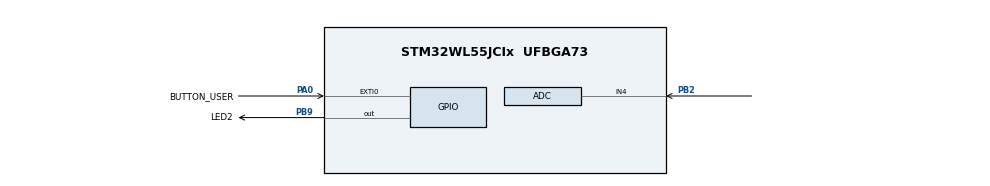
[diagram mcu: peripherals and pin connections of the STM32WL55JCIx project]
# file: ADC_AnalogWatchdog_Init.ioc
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ADC.AWD1HighThreshold=ADC_AWD_THRESHOLD_HIGH
ADC.AWD1ITMode=ENABLE
ADC.AWD1LowThreshold=ADC_AWD_THRESHOLD_LOW
ADC.Channel-0\#ChannelRegularConversion=ADC_CHANNEL_4
ADC.ClockPrescaler=ADC_CLOCK_SYNC_PCLK_DIV4
ADC.ContinuousConvMode=ENABLE
ADC.DMAContinuousRequests=DISABLE
ADC.DataAlign=ADC_DATAALIGN_RIGHT
ADC.DiscontinuousConvMode=DISABLE
ADC.EOCSelection=ADC_EOC_SINGLE_CONV
ADC.EnableAnalogWatchDog1=true
ADC.EnableAnalogWatchDog2=false
ADC.EnableAnalogWatchDog3=false
ADC.EnableRegularConversion=ENABLE
ADC.ExternalTrigConv=ADC_SOFTWARE_START
ADC.ExternalTrigConvEdge=ADC_EXTERNALTRIGCONVEDGE_NONE
ADC.LowPowerAutoPowerOff=DISABLE
ADC.LowPowerAutoWait=DISABLE
ADC.NbrOfConversion=1
ADC.NbrOfConversionFlag=1
ADC.Overrun=ADC_OVR_DATA_OVERWRITTEN
ADC.OversamplingMode=DISABLE
ADC.Rank-0\#ChannelRegularConversion=1
ADC.Resolution=ADC_RESOLUTION_12B
ADC.SamplingTime-0\#ChannelRegularConversion=ADC_SAMPLINGTIME_COMMON_1
ADC.SamplingTimeCommon1=ADC_SAMPLETIME_160CYCLES_5
ADC.SamplingTimeCommon2=ADC_SAMPLETIME_160CYCLES_5
ADC.ScanConvMode=ADC_SCAN_DISABLE
ADC.SelectedChannel=ADC_CHANNEL_4|ADC_CHANNEL_VREFINT
ADC.Sequencer=FULLY_CONFIGURABLE
ADC.TriggerFrequencyMode=ADC_TRIGGER_FREQ_HIGH
ADC.WatchdogMode=ADC_ANALOGWATCHDOG_ALL_REG
Mcu.Family=STM32WL
Mcu.Name=STM32WL55JCIx
Mcu.Package=UFBGA73
NVIC.EXTI0_IRQn=true\:0\:0\:false\:false\:true\:true\:true
NVIC.PriorityGroup=NVIC_PRIORITYGROUP_4
PA0.GPIO_Label=BUTTON_USER
PA0.GPIO_ModeDefaultEXTI=GPIO_MODE_IT_FALLING
PA0.GPIO_PuPd=GPIO_PULLUP
PA0.Signal=GPXTI0
PB2.Mode=IN4
PB2.Signal=ADC_IN4
PB9.GPIO_Label=LED2
PB9.Signal=GPIO_Output
ProjectManager.HeapSize=0x200
ProjectManager.StackSize=0x400
ProjectManager.TargetToolchain=EWARM V8
RCC.AHBFreq_Value=48000000
RCC.APB1Freq_Value=48000000
RCC.APB1TimFreq_Value=48000000
RCC.APB2Freq_Value=48000000
RCC.APB2TimFreq_Value=48000000
RCC.APB3Freq_Value=48000000
RCC.CortexFreq_Value=48000000
RCC.HCLKFreq_Value=48000000
RCC.HSE_VALUE=8000000
RCC.HSI_VALUE=16000000
RCC.LSE_VALUE=32768
RCC.MSIClockRange=RCC_MSIRANGE_11
RCC.SYSCLKFreq_VALUE=48000000
RCC.VCOOutputFreq_Value=384000000
VP_ADC_Vref_Input.Mode=IN-Vrefint
board=custom

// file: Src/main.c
/* USER CODE BEGIN Header */
/**
  ******************************************************************************
  * @file    Examples_LL/ADC/ADC_AnalogWatchdog_Init/Src/main.c
  * @author  MCD Application Team
  * @brief   This example describes how to use a ADC peripheral
  *          with ADC analog watchdog to monitor a channel and detect
  *          when the corresponding conversion data is out of window thresholds.
  *          This example is based on the STM32WLxx ADC LL API;
  *          Peripheral initialization done using LL unitary services functions.
  ******************************************************************************
  * @attention
  *
  * <h2><center>&copy; Copyright (c) 2020 STMicroelectronics.
  * All rights reserved.</center></h2>
  *
  * This software component is licensed by ST under BSD 3-Clause license,
  * the "License"; You may not use this file except in compliance with the
  * License. You may obtain a copy of the License at:
  *                        opensource.org/licenses/BSD-3-Clause
  *
  ******************************************************************************
  */
/* USER CODE END Header */
#include "main.h"

/* USER CODE BEGIN PD */

/* Definitions of ADC hardware constraints delays */
/* Note: Only ADC IP HW delays are defined in ADC LL driver driver,           */
/*       not timeout values:                                                  */
/*       Timeout values for ADC operations are dependent to device clock      */
/*       configuration (system clock versus ADC clock),                       */
/*       and therefore must be defined in user application.                   */
/*       Refer to @ref ADC_LL_EC_HW_DELAYS for description of ADC timeout     */
/*       values definition.                                                   */

  /* Timeout values for ADC operations. */
  /* (calibration, enable settling time, disable settling time, ...)          */
  /* Values defined to be higher than worst cases: low clock frequency,       */
  /* maximum prescalers.                                                      */
  /* Unit: ms                                                                 */
  #define ADC_CALIBRATION_TIMEOUT_MS       (   1U)
  #define ADC_ENABLE_TIMEOUT_MS            (   1U)
  #define ADC_DISABLE_TIMEOUT_MS           (   1U)
  #define ADC_STOP_CONVERSION_TIMEOUT_MS   (   1U)
  #define ADC_CONVERSION_TIMEOUT_MS        (4000U)

  /* Delay between ADC end of calibration and ADC enable.                     */
  /* Delay estimation in CPU cycles: Case of ADC enable done                  */
  /* immediately after ADC calibration, ADC clock setting slow                */
  /* (LL_ADC_CLOCK_ASYNC_DIV32). Use a higher delay if ratio                  */
  /* (CPU clock / ADC clock) is above 32.                                     */
  #define ADC_DELAY_CALIB_ENABLE_CPU_CYCLES  (LL_ADC_DELAY_CALIB_ENABLE_ADC_CYCLES * 32)

/* Definitions of environment analog values */
  /* Value of analog reference voltage (Vref+), connected to analog voltage   */
  /* supply Vdda (unit: mV).                                                  */
  #define VDDA_APPLI                       (3300UL)

/* Definitions of data related to this example */
  /* Definition of ADCx analog watchdog window thresholds */
  /* Value of ADC analog watchdog threshold high */
  #define ADC_AWD_THRESHOLD_HIGH           (__LL_ADC_DIGITAL_SCALE(LL_ADC_RESOLUTION_12B) / 2)
  /* Value of ADC analog watchdog threshold low  */
  #define ADC_AWD_THRESHOLD_LOW            (   0UL)

/* USER CODE END PD */

/* USER CODE BEGIN PV */

/* Variable to report status of ADC analog watchdog 1:                        */
/*  0: ADC conversion data into AWD window                                    */
/*  1: ADC conversion data out of AWD window                                  */
__IO   uint8_t ubAnalogWatchdog1Status = 0U; /* Variable set into analog watchdog 1 interruption callback */

/* USER CODE END PV */

void SystemClock_Config(void);
static void MX_GPIO_Init(void);
static void MX_ADC_Init(void);
/* USER CODE BEGIN PFP */

void     Activate_ADC(void);
void     LED_On(void);
void     LED_Off(void);
void     LED_Blinking(uint32_t Period);

/* USER CODE END PFP */

int main(void)
{

  /* MCU Configuration--------------------------------------------------------*/

  /* Reset of all peripherals, Initializes the Flash interface and the Systick. */

  NVIC_SetPriorityGrouping(NVIC_PRIORITYGROUP_4);

  /* System interrupt init*/

  /* Configure the system clock */
  SystemClock_Config();

  /* Initialize all configured peripherals */
  MX_GPIO_Init();
  MX_ADC_Init();
  /* USER CODE BEGIN 2 */

  /* Activate ADC */
  /* Perform ADC activation procedure to make it ready to convert. */
  Activate_ADC();

  /* Start ADC group regular conversion */
  /* Note: Hardware constraint (refer to description of the functions         */
  /*       below):                                                            */
  /*       On this STM32 series, setting of this feature is conditioned to     */
  /*       ADC state:                                                         */
  /*       ADC must be enabled without conversion on going on group regular,  */
  /*       without ADC disable command on going.                              */
  /* Note: In this example, all these checks are not necessary but are        */
  /*       implemented anyway to show the best practice usages                */
  /*       corresponding to reference manual procedure.                       */
  /*       Software can be optimized by removing some of these checks, if     */
  /*       they are not relevant considering previous settings and actions    */
  /*       in user application.                                               */
  if ((LL_ADC_IsEnabled(ADC) == 1)               &&
      (LL_ADC_IsDisableOngoing(ADC) == 0)        &&
      (LL_ADC_REG_IsConversionOngoing(ADC) == 0)   )
  {
    LL_ADC_REG_StartConversion(ADC);
  }
  else
  {
    /* Error: ADC conversion start could not be performed */
    LED_Blinking(LED_BLINK_ERROR);
  }

  /* USER CODE END 2 */

  /* Infinite loop */
  while (1)
  {

    /* USER CODE BEGIN 3 */
    /* Note: LED state depending on ADC analog watchdog 1 status              */
    /*       and status variable "ubAnalogWatchdog1Status"                    */
    /*       are set into ADC analog watchdog 1 IRQ handler,                  */
    /*       refer to function "AdcAnalogWatchdog1_Callback()".               */
    /*       After analog watchdog interruption, press on push button         */
    /*       to rearm ADC analog watchdog to be ready for another trig,       */
    /*       refer to function "UserButton_Callback()".                       */
  }
  /* USER CODE END 3 */
}

void SystemClock_Config(void)
{
  LL_FLASH_SetLatency(LL_FLASH_LATENCY_2);
  while(LL_FLASH_GetLatency() != LL_FLASH_LATENCY_2)
  {
  }

  LL_PWR_SetRegulVoltageScaling(LL_PWR_REGU_VOLTAGE_SCALE1);
  LL_RCC_MSI_Enable();

   /* Wait till MSI is ready */
  while(LL_RCC_MSI_IsReady() != 1)
  {
  }

  LL_RCC_MSI_EnableRangeSelection();
  LL_RCC_MSI_SetRange(LL_RCC_MSIRANGE_11);
  LL_RCC_MSI_SetCalibTrimming(0);
  LL_RCC_SetSysClkSource(LL_RCC_SYS_CLKSOURCE_MSI);

   /* Wait till System clock is ready */
  while(LL_RCC_GetSysClkSource() != LL_RCC_SYS_CLKSOURCE_STATUS_MSI)
  {
  }

  LL_RCC_SetAHBPrescaler(LL_RCC_SYSCLK_DIV_1);
  LL_RCC_SetAHB3Prescaler(LL_RCC_SYSCLK_DIV_1);
  LL_RCC_SetAPB1Prescaler(LL_RCC_APB1_DIV_1);
  LL_RCC_SetAPB2Prescaler(LL_RCC_APB2_DIV_1);

  LL_Init1msTick(48000000);

  /* Update CMSIS variable (which can be updated also through SystemCoreClockUpdate function) */
  LL_SetSystemCoreClock(48000000);
}

static void MX_ADC_Init(void)
{

  LL_ADC_InitTypeDef ADC_InitStruct = {0};
  LL_ADC_REG_InitTypeDef ADC_REG_InitStruct = {0};

  LL_GPIO_InitTypeDef GPIO_InitStruct = {0};

  /* Peripheral clock enable */
  LL_APB2_GRP1_EnableClock(LL_APB2_GRP1_PERIPH_ADC);

  LL_AHB2_GRP1_EnableClock(LL_AHB2_GRP1_PERIPH_GPIOB);
  /**ADC GPIO Configuration
  PB2   ------> ADC_IN4
  */
  GPIO_InitStruct.Pin = LL_GPIO_PIN_2;
  GPIO_InitStruct.Mode = LL_GPIO_MODE_ANALOG;
  GPIO_InitStruct.Pull = LL_GPIO_PULL_NO;
  LL_GPIO_Init(GPIOB, &GPIO_InitStruct);

  /* USER CODE BEGIN ADC_Init 1 */

  /* Enable GPIO Clock */
  LL_AHB2_GRP1_EnableClock(LL_AHB2_GRP1_PERIPH_GPIOB);

  /* Configure GPIO in analog mode to be used as ADC input */
  LL_GPIO_SetPinMode(GPIOB, LL_GPIO_PIN_2, LL_GPIO_MODE_ANALOG);

  /*## Configuration of NVIC #################################################*/
  /* Configure NVIC to enable ADC interruptions */
  NVIC_SetPriority(ADC_IRQn, 0);
  NVIC_EnableIRQ(ADC_IRQn);

  /* USER CODE END ADC_Init 1 */
  /** Configure the global features of the ADC (Clock, Resolution, Data Alignment and number of conversion)
  */

   #define ADC_CHANNEL_CONF_RDY_TIMEOUT_MS ( 1U)
   #if (USE_TIMEOUT == 1)
   uint32_t Timeout ; /* Variable used for Timeout management */
   #endif /* USE_TIMEOUT */

  ADC_InitStruct.Clock = LL_ADC_CLOCK_SYNC_PCLK_DIV4;
  ADC_InitStruct.Resolution = LL_ADC_RESOLUTION_12B;
  ADC_InitStruct.DataAlignment = LL_ADC_DATA_ALIGN_RIGHT;
  ADC_InitStruct.LowPowerMode = LL_ADC_LP_MODE_NONE;
  LL_ADC_Init(ADC, &ADC_InitStruct);
  LL_ADC_REG_SetSequencerConfigurable(ADC, LL_ADC_REG_SEQ_CONFIGURABLE);

   /* Poll for ADC channel configuration ready */
   #if (USE_TIMEOUT == 1)
   Timeout = ADC_CHANNEL_CONF_RDY_TIMEOUT_MS;
   #endif /* USE_TIMEOUT */
   while (LL_ADC_IsActiveFlag_CCRDY(ADC) == 0)
     {
   #if (USE_TIMEOUT == 1)
   /* Check Systick counter flag to decrement the time-out value */
   if (LL_SYSTICK_IsActiveCounterFlag())
     {
   if(Timeout-- == 0)
         {
   Error_Handler();
         }
     }
   #endif /* USE_TIMEOUT */
     }
   /* Clear flag ADC channel configuration ready */
   LL_ADC_ClearFlag_CCRDY(ADC);
  ADC_REG_InitStruct.TriggerSource = LL_ADC_REG_TRIG_SOFTWARE;
  ADC_REG_InitStruct.SequencerLength = LL_ADC_REG_SEQ_SCAN_DISABLE;
  ADC_REG_InitStruct.SequencerDiscont = LL_ADC_REG_SEQ_DISCONT_DISABLE;
  ADC_REG_InitStruct.ContinuousMode = LL_ADC_REG_CONV_CONTINUOUS;
  ADC_REG_InitStruct.DMATransfer = LL_ADC_REG_DMA_TRANSFER_NONE;
  ADC_REG_InitStruct.Overrun = LL_ADC_REG_OVR_DATA_OVERWRITTEN;
  LL_ADC_REG_Init(ADC, &ADC_REG_InitStruct);

   /* Enable ADC internal voltage regulator */
   LL_ADC_EnableInternalRegulator(ADC);
   /* Delay for ADC internal voltage regulator stabilization. */
   /* Compute number of CPU cycles to wait for, from delay in us. */
   /* Note: Variable divided by 2 to compensate partially */
   /* CPU processing cycles (depends on compilation optimization). */
   /* Note: If system core clock frequency is below 200kHz, wait time */
   /* is only a few CPU processing cycles. */
   uint32_t wait_loop_index;
   wait_loop_index = ((LL_ADC_DELAY_INTERNAL_REGUL_STAB_US * (SystemCoreClock / (100000 * 2))) / 10);
   while(wait_loop_index != 0)
     {
   wait_loop_index--;
     }
  LL_ADC_SetOverSamplingScope(ADC, LL_ADC_OVS_DISABLE);
  LL_ADC_SetSamplingTimeCommonChannels(ADC, LL_ADC_SAMPLINGTIME_COMMON_1, LL_ADC_SAMPLINGTIME_160CYCLES_5);
  LL_ADC_SetSamplingTimeCommonChannels(ADC, LL_ADC_SAMPLINGTIME_COMMON_2, LL_ADC_SAMPLINGTIME_160CYCLES_5);
  LL_ADC_DisableIT_EOC(ADC);
  LL_ADC_DisableIT_EOS(ADC);
  LL_ADC_SetTriggerFrequencyMode(ADC, LL_ADC_TRIGGER_FREQ_HIGH);
  /** Configure Analog WatchDog 1
  */
  LL_ADC_SetAnalogWDMonitChannels(ADC, LL_ADC_AWD1, LL_ADC_AWD_ALL_CHANNELS_REG);
  LL_ADC_ConfigAnalogWDThresholds(ADC, LL_ADC_AWD1, ADC_AWD_THRESHOLD_HIGH, ADC_AWD_THRESHOLD_LOW);
  LL_ADC_EnableIT_AWD1(ADC);
  /** Configure Regular Channel
  */
  LL_ADC_REG_SetSequencerRanks(ADC, LL_ADC_REG_RANK_1, LL_ADC_CHANNEL_4);

   /* Poll for ADC channel configuration ready */
   #if (USE_TIMEOUT == 1)
   Timeout = ADC_CHANNEL_CONF_RDY_TIMEOUT_MS;
   #endif /* USE_TIMEOUT */
   while (LL_ADC_IsActiveFlag_CCRDY(ADC) == 0)
     {
   #if (USE_TIMEOUT == 1)
   /* Check Systick counter flag to decrement the time-out value */
   if (LL_SYSTICK_IsActiveCounterFlag())
     {
   if(Timeout-- == 0)
         {
   Error_Handler();
         }
     }
   #endif /* USE_TIMEOUT */
     }
   /* Clear flag ADC channel configuration ready */
   LL_ADC_ClearFlag_CCRDY(ADC);
  LL_ADC_SetChannelSamplingTime(ADC, LL_ADC_CHANNEL_4, LL_ADC_SAMPLINGTIME_COMMON_1);

}

static void MX_GPIO_Init(void)
{
  LL_EXTI_InitTypeDef EXTI_InitStruct = {0};
  LL_GPIO_InitTypeDef GPIO_InitStruct = {0};

  /* GPIO Ports Clock Enable */
  LL_AHB2_GRP1_EnableClock(LL_AHB2_GRP1_PERIPH_GPIOB);
  LL_AHB2_GRP1_EnableClock(LL_AHB2_GRP1_PERIPH_GPIOA);

  /**/
  LL_GPIO_ResetOutputPin(LED2_GPIO_Port, LED2_Pin);

  /**/
  GPIO_InitStruct.Pin = LED2_Pin;
  GPIO_InitStruct.Mode = LL_GPIO_MODE_OUTPUT;
  GPIO_InitStruct.Speed = LL_GPIO_SPEED_FREQ_LOW;
  GPIO_InitStruct.OutputType = LL_GPIO_OUTPUT_PUSHPULL;
  GPIO_InitStruct.Pull = LL_GPIO_PULL_NO;
  LL_GPIO_Init(LED2_GPIO_Port, &GPIO_InitStruct);

  /**/
  LL_SYSCFG_SetEXTISource(LL_SYSCFG_EXTI_PORTA, LL_SYSCFG_EXTI_LINE0);

  /**/
  EXTI_InitStruct.Line_0_31 = LL_EXTI_LINE_0;
  EXTI_InitStruct.Line_32_63 = LL_EXTI_LINE_NONE;
  EXTI_InitStruct.LineCommand = ENABLE;
  EXTI_InitStruct.Mode = LL_EXTI_MODE_IT;
  EXTI_InitStruct.Trigger = LL_EXTI_TRIGGER_FALLING;
  LL_EXTI_Init(&EXTI_InitStruct);

  /**/
  LL_GPIO_SetPinPull(BUTTON_USER_GPIO_Port, BUTTON_USER_Pin, LL_GPIO_PULL_UP);

  /**/
  LL_GPIO_SetPinMode(BUTTON_USER_GPIO_Port, BUTTON_USER_Pin, LL_GPIO_MODE_INPUT);

  /* EXTI interrupt init*/
  NVIC_SetPriority(EXTI0_IRQn, NVIC_EncodePriority(NVIC_GetPriorityGrouping(),0, 0));
  NVIC_EnableIRQ(EXTI0_IRQn);

}

/* USER CODE BEGIN 4 */

/**
  * @brief  Perform ADC activation procedure to make it ready to convert
  *         (ADC instance: ADC).
  * @note   Operations:
  *         - ADC instance
  *           - Run ADC self calibration
  *           - Enable ADC
  *         - ADC group regular
  *           none: ADC conversion start-stop to be performed
  *                 after this function
  *         - ADC group injected
  *           Feature not available                                  (feature not available on this STM32 series)
  * @param  None
  * @retval None
  */
void Activate_ADC(void)
{
  __IO uint32_t wait_loop_index = 0U;
  __IO uint32_t backup_setting_adc_dma_transfer = 0U;
  #if (USE_TIMEOUT == 1)
  uint32_t Timeout = 0U; /* Variable used for timeout management */
  #endif /* USE_TIMEOUT */

  /*## Operation on ADC hierarchical scope: ADC instance #####################*/

  /* Note: Hardware constraint (refer to description of the functions         */
  /*       below):                                                            */
  /*       On this STM32 series, setting of these features is conditioned to   */
  /*       ADC state:                                                         */
  /*       ADC must be disabled.                                              */
  /* Note: In this example, all these checks are not necessary but are        */
  /*       implemented anyway to show the best practice usages                */
  /*       corresponding to reference manual procedure.                       */
  /*       Software can be optimized by removing some of these checks, if     */
  /*       they are not relevant considering previous settings and actions    */
  /*       in user application.                                               */
  if (LL_ADC_IsEnabled(ADC) == 0)
  {
    /* Enable ADC internal voltage regulator */
    LL_ADC_EnableInternalRegulator(ADC);

    /* Delay for ADC internal voltage regulator stabilization.                */
    /* Compute number of CPU cycles to wait for, from delay in us.            */
    /* Note: Variable divided by 2 to compensate partially                    */
    /*       CPU processing cycles (depends on compilation optimization).     */
    /* Note: If system core clock frequency is below 200kHz, wait time        */
    /*       is only a few CPU processing cycles.                             */
    wait_loop_index = ((LL_ADC_DELAY_INTERNAL_REGUL_STAB_US * (SystemCoreClock / (100000 * 2))) / 10);
    while(wait_loop_index != 0)
    {
      wait_loop_index--;
    }

    /* Disable ADC DMA transfer request during calibration */
    /* Note: Specificity of this STM32 series: Calibration factor is           */
    /*       available in data register and also transferred by DMA.           */
    /*       To not insert ADC calibration factor among ADC conversion data   */
    /*       in DMA destination address, DMA transfer must be disabled during */
    /*       calibration.                                                     */
    backup_setting_adc_dma_transfer = LL_ADC_REG_GetDMATransfer(ADC);
    LL_ADC_REG_SetDMATransfer(ADC, LL_ADC_REG_DMA_TRANSFER_NONE);

    /* Run ADC self calibration */
    LL_ADC_StartCalibration(ADC);

    /* Poll for ADC effectively calibrated */
    #if (USE_TIMEOUT == 1)
    Timeout = ADC_CALIBRATION_TIMEOUT_MS;
    #endif /* USE_TIMEOUT */

    while (LL_ADC_IsCalibrationOnGoing(ADC) != 0)
    {
    #if (USE_TIMEOUT == 1)
      /* Check Systick counter flag to decrement the time-out value */
      if (LL_SYSTICK_IsActiveCounterFlag())
      {
        if(Timeout-- == 0)
        {
        /* Time-out occurred. Set LED to blinking mode */
        LED_Blinking(LED_BLINK_ERROR);
        }
      }
    #endif /* USE_TIMEOUT */
    }

    /* Restore ADC DMA transfer request after calibration */
    LL_ADC_REG_SetDMATransfer(ADC, backup_setting_adc_dma_transfer);

    /* Delay between ADC end of calibration and ADC enable.                   */
    /* Note: Variable divided by 2 to compensate partially                    */
    /*       CPU processing cycles (depends on compilation optimization).     */
    wait_loop_index = (ADC_DELAY_CALIB_ENABLE_CPU_CYCLES >> 1);
    while(wait_loop_index != 0)
    {
      wait_loop_index--;
    }

    /* Enable ADC */
    LL_ADC_Enable(ADC);

    /* Poll for ADC ready to convert */
    #if (USE_TIMEOUT == 1)
    Timeout = ADC_ENABLE_TIMEOUT_MS;
    #endif /* USE_TIMEOUT */

    while (LL_ADC_IsActiveFlag_ADRDY(ADC) == 0)
    {
    #if (USE_TIMEOUT == 1)
      /* Check Systick counter flag to decrement the time-out value */
      if (LL_SYSTICK_IsActiveCounterFlag())
      {
        if(Timeout-- == 0)
        {
        /* Time-out occurred. Set LED to blinking mode */
        LED_Blinking(LED_BLINK_ERROR);
        }
      }
    #endif /* USE_TIMEOUT */
    }

    /* Note: ADC flag ADRDY is not cleared here to be able to check ADC       */
    /*       status afterwards.                                               */
    /*       This flag should be cleared at ADC Deactivation, before a new    */
    /*       ADC activation, using function "LL_ADC_ClearFlag_ADRDY()".       */
  }

  /*## Operation on ADC hierarchical scope: ADC group regular ################*/
  /* Note: No operation on ADC group regular performed here.                  */
  /*       ADC group regular conversions to be performed after this function  */
  /*       using function:                                                    */
  /*       "LL_ADC_REG_StartConversion();"                                    */

  /*## Operation on ADC hierarchical scope: ADC group injected ###############*/
  /* Note: Feature not available on this STM32 series */

}

/**
  * @brief  Turn-on LED2.
  * @param  None
  * @retval None
  */
void LED_On(void)
{
  /* Turn LED2 on */
  LL_GPIO_SetOutputPin(LED2_GPIO_Port, LED2_Pin);
}

/**
  * @brief  Turn-off LED2.
  * @param  None
  * @retval None
  */
void LED_Off(void)
{
  /* Turn LED2 off */
  LL_GPIO_ResetOutputPin(LED2_GPIO_Port, LED2_Pin);
}

/**
  * @brief  Set LED2 to Blinking mode for an infinite loop (toggle period based on value provided as input parameter).
  * @param  Period : Period of time (in ms) between each toggling of LED
  *   This parameter can be user defined values. Pre-defined values used in that example are :
  *     @arg LED_BLINK_FAST : Fast Blinking
  *     @arg LED_BLINK_SLOW : Slow Blinking
  *     @arg LED_BLINK_ERROR : Error specific Blinking
  * @retval None
  */
void LED_Blinking(uint32_t Period)
{
  /* Turn LED2 on */
  LL_GPIO_SetOutputPin(LED2_GPIO_Port, LED2_Pin);

  /* Toggle IO in an infinite loop */
  while (1)
  {
    LL_GPIO_TogglePin(LED2_GPIO_Port, LED2_Pin);
    LL_mDelay(Period);
  }
}

/******************************************************************************/
/*   USER IRQ HANDLER TREATMENT                                               */
/******************************************************************************/

/**
  * @brief  Function to manage IRQ Handler
  * @param  None
  * @retval None
  */
void UserButton_Callback(void)
{
  /* Rearm ADC analog watchdog to be ready for another trig */

  /* Turn LED2 off */
  LED_Off();

  /* Reset status variable of ADC analog watchdog 1 */
  ubAnalogWatchdog1Status = 0;

  /* Clear flag ADC analog watchdog 1 */
  LL_ADC_ClearFlag_AWD1(ADC);

  /* Enable ADC analog watchdog 1 interruption */
  LL_ADC_EnableIT_AWD1(ADC);
}

/**
  * @brief  ADC analog watchdog 1 interruption callback
  * @note   This function is executed when the ADC conversion data is
  *         out of analog watchdog 1 window thresholds.
  * @retval None
  */
void AdcAnalogWatchdog1_Callback()
{
  /* Disable ADC analog watchdog 1 interruption */
  LL_ADC_DisableIT_AWD1(ADC);

  /* Update status variable of ADC analog watchdog 1 */
  ubAnalogWatchdog1Status = 1;

  /* Set LED depending on ADC analog watchdog status */
  /* - Turn-on if voltage is out of AWD window */
  LED_On();
}

/* USER CODE END 4 */

void Error_Handler(void)
{
}

/************************ (C) COPYRIGHT STMicroelectronics *****END OF FILE****/
